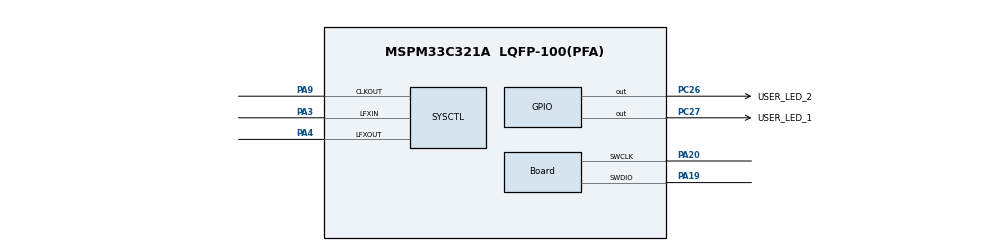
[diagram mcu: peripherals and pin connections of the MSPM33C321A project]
//@cliArgs --device "MSPM33C321A" --package "LQFP-100(PFA)" --part "Default"
//@v2CliArgs --device "MSPM33C321A" --package "LQFP-100(PFA)"
// @cliArgs --board /ti/boards/LP_MSPM33C321A --rtos nortos


/**
 * Import the modules used in this configuration.
 */
const GPIO   = scripting.addModule("/ti/driverlib/GPIO", {}, false);
const GPIO1  = GPIO.addInstance();
const SYSCTL = scripting.addModule("/ti/driverlib/SYSCTL");
const TIMER  = scripting.addModule("/ti/driverlib/TIMER", {}, false);
const TIMER1 = TIMER.addInstance();


/**
 * Write custom configuration values to the imported modules.
 */
GPIO1.$name                                 = "GPIO_LEDS";
GPIO1.associatedPins.create(2);
GPIO1.associatedPins[0].assignedPort        = "PORTC";
GPIO1.associatedPins[0].assignedPortSegment = "Upper";
GPIO1.associatedPins[0].assignedPin         = "26";
GPIO1.associatedPins[0].launchPadShortcut   = "LED2RedEn";
GPIO1.associatedPins[0].$name               = "USER_LED_2";
GPIO1.associatedPins[0].pin.$assign         = "PC26";
GPIO1.associatedPins[1].launchPadShortcut   = "LED2GreenEn";
GPIO1.associatedPins[1].$name               = "USER_LED_1";
GPIO1.associatedPins[1].pin.$assign         = "PC27";

const Board                       = scripting.addModule("/ti/driverlib/Board", {}, false);
Board.peripheral.$assign          = "DEBUGSS";
Board.peripheral.swclkPin.$assign = "PA20";
Board.peripheral.swdioPin.$assign = "PA19";

SYSCTL.forceDefaultClkConfig        = true;
SYSCTL.enableEXCLK                  = true;
SYSCTL.fccTrigSrc                   = "LFCLK";
SYSCTL.fccClkSrc                    = "SYSOSC";
SYSCTL.fccPeriods                   = "02";
SYSCTL.HFCLKSource                  = "HFXT";
SYSCTL.HFCLK_Freq                   = 40000000;
SYSCTL.HFXTStartup                  = 10;
SYSCTL.HFCLKMonitor                 = true;
SYSCTL.HSCLKSource                  = "HFCLK";
SYSCTL.LFCLKSource                  = "LFXT";
SYSCTL.EXCLKSource                  = "LFCLK";
SYSCTL.powerPolicy                  = "STANDBY0";
SYSCTL.peripheral.$assign           = "SYSCTL";
SYSCTL.peripheral.lfxInPin.$assign  = "PA3";
SYSCTL.peripheral.lfxOutPin.$assign = "PA4";
SYSCTL.peripheral.clkOutPin.$assign = "PA9";

TIMER1.$name              = "TIMER_0";
TIMER1.timerClkPrescale   = 129;
TIMER1.timerPeriod        = "500 ms";
TIMER1.timerMode          = "PERIODIC";
TIMER1.interrupts         = ["ZERO"];
TIMER1.timerClkSrc        = "LFCLK";
TIMER1.peripheral.$assign = "TIMG4_0";

const ProjectConfig              = scripting.addModule("/ti/project_config/ProjectConfig", {}, false);
ProjectConfig.migrationCondition = true;

ProjectConfig.genLinker  = true;
ProjectConfig.genStartup = true;
ProjectConfig.genOpts    = true;
ProjectConfig.genLibs    = true;
